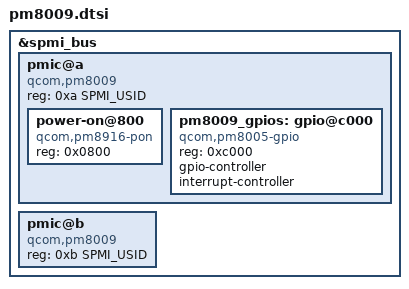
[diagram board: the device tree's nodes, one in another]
// SPDX-License-Identifier: BSD-3-Clause
/*
 * Copyright (c) 2017-2019, The Linux Foundation. All rights reserved.
 * Copyright (c) 2019, Linaro Limited
 */

#include <dt-bindings/input/input.h>
#include <dt-bindings/interrupt-controller/irq.h>
#include <dt-bindings/spmi/spmi.h>
#include <dt-bindings/iio/qcom,spmi-vadc.h>

&spmi_bus {
	pmic@a {
		compatible = "qcom,pm8009", "qcom,spmi-pmic";
		reg = <0xa SPMI_USID>;
		#address-cells = <1>;
		#size-cells = <0>;

		power-on@800 {
			compatible = "qcom,pm8916-pon";
			reg = <0x0800>;
		};

		pm8009_gpios: gpio@c000 {
			compatible = "qcom,pm8005-gpio";
			reg = <0xc000>;
			gpio-controller;
			#gpio-cells = <2>;
			interrupt-controller;
			#interrupt-cells = <2>;
		};
	};

	pmic@b {
		compatible = "qcom,pm8009", "qcom,spmi-pmic";
		reg = <0xb SPMI_USID>;
		#address-cells = <1>;
		#size-cells = <0>;
	};
};
